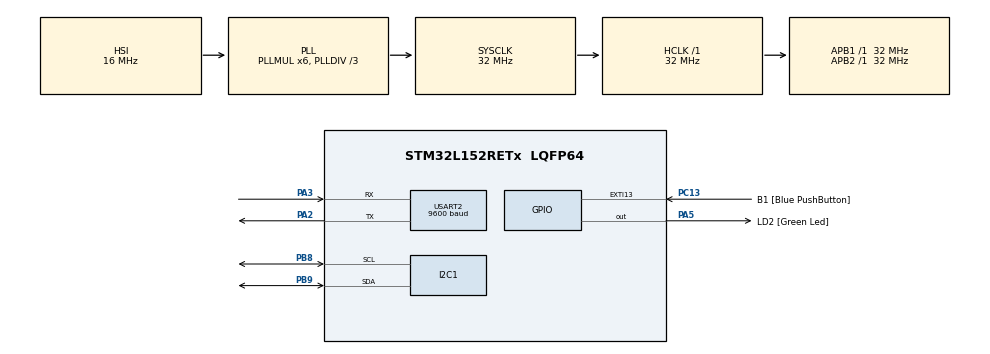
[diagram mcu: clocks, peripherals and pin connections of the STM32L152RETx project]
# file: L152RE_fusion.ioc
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Mcu.Family=STM32L1
Mcu.Name=STM32L152RETx
Mcu.Package=LQFP64
NVIC.PriorityGroup=NVIC_PRIORITYGROUP_0
NVIC.RCC_IRQn=true\:0\:0\:false\:false\:true\:true
NVIC.TIM3_IRQn=true\:0\:0\:false\:false\:true\:true
PA2.Mode=Asynchronous
PA2.Signal=USART2_TX
PA3.Mode=Asynchronous
PA3.Signal=USART2_RX
PA5.GPIO_Label=LD2 [Green Led]
PA5.Signal=GPIO_Output
PB8.Mode=I2C
PB8.Signal=I2C1_SCL
PB9.Mode=I2C
PB9.Signal=I2C1_SDA
PC13-WKUP2.GPIO_Label=B1 [Blue PushButton]
PC13-WKUP2.Signal=GPXTI13
PH0-OSC_IN.Mode=HSE-External-Oscillator
PH0-OSC_IN.Signal=RCC_OSC_IN
PH1-OSC_OUT.Mode=HSE-External-Oscillator
PH1-OSC_OUT.Signal=RCC_OSC_OUT
ProjectManager.HeapSize=0x200
ProjectManager.StackSize=0x400
ProjectManager.TargetToolchain=SW4STM32
RCC.AHBFreq_Value=32000000
RCC.APB1Freq_Value=32000000
RCC.APB1TimFreq_Value=32000000
RCC.APB2Freq_Value=32000000
RCC.APB2TimFreq_Value=32000000
RCC.HCLKFreq_Value=32000000
RCC.HSE_VALUE=8000000
RCC.HSI_VALUE=16000000
RCC.LSE_VALUE=32768
RCC.MSI_VALUE=2097000
RCC.PLLDIV=RCC_PLL_DIV3
RCC.PLLMUL=RCC_PLL_MUL6
RCC.RTCClockSelectionVirtual=RCC_RTCCLKSOURCE_LSE
RCC.SYSCLKFreq_VALUE=32000000
RCC.SYSCLKSource=RCC_SYSCLKSOURCE_PLLCLK
RCC.USBOutput=48000000
RCC.VCOOutputFreq_Value=96000000
TIM3.Period=499
TIM3.Prescaler=15999
USART2.BaudRate=9600
USART2.VirtualMode=VM_ASYNC
VP_TIM3_VS_ClockSourceINT.Mode=Internal
board=NUCLEO-L152RE

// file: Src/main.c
/**
 ******************************************************************************
 * File Name          : main.c
 * Description        : Main program body
 ******************************************************************************
 ******************************************************************************
 */

#include "main.h"
#include "stm32l1xx_hal.h"

/* USER CODE BEGIN Includes */
#include "LSM303AGR_driver.h"
#include <stdio.h>
#include <stdarg.h>
#include <string.h>
/* USER CODE END Includes */

I2C_HandleTypeDef hi2c1;
TIM_HandleTypeDef htim3;
UART_HandleTypeDef huart2;

/* USER CODE BEGIN PV */
/* Private variables ---------------------------------------------------------*/

/* USER CODE END PV */

void SystemClock_Config(void);
static void MX_GPIO_Init(void);
static void MX_I2C1_Init(void);
static void MX_USART2_UART_Init(void);
static void MX_TIM3_Init(void);

/* USER CODE BEGIN PFP */
/* Private function prototypes -----------------------------------------------*/

/* USER CODE END PFP */
void vprint(const char *fmt, va_list argp);
void my_printf(const char *fmt);
//void write_register(uint8_t register_pointer, uint16_t register_value);
//void read_register(uint8_t register_pointer, uint16_t register_value);
/* USER CODE END PFP */

int main(void) {

	/* MCU Configuration----------------------------------------------------------*/
	/* Reset of all peripherals, Initializes the Flash interface and the Systick. */
	HAL_Init();

	/* Configure the system clock */
	SystemClock_Config();

	/* Initialize all configured peripherals */
	MX_GPIO_Init();
	MX_I2C1_Init();
	MX_USART2_UART_Init();
	MX_TIM3_Init();

	/* Infinite loop */
	while (1) {

//		char message[] = "Start test\n\r";
//
//		HAL_UART_Transmit(&huart2, (uint8_t*)message, strlen(message), 1000);
//		HAL_Delay(2000);
//
//		/* USER CODE BEGIN 3 */
//		//https://electronics.stackexchange.com/questions/244491/addressing-registers-with-i2c-stm32f0-hal-libraries
//		uint8_t buffer = 0b01000001;
//
//		// Set the register pointer to the register wanted to be read
//		HAL_I2C_Master_Transmit(&hi2c1, LSM303AGR_M_I2C_ADDRESS<<1,
//				LSM303AGR_A_WHO_AM_I_REG, 1, 100);
//
//		// Receive the 8-bit data into the buffer
//		HAL_I2C_Master_Receive(&hi2c1, LSM303AGR_A_I2C_ADDRESS, buffer, 1, 100);
//
//		char message1[] = "start I2C reading\n\r";
//		HAL_UART_Transmit(&huart2, (uint8_t*)message1, strlen(message1), 1000);
//		HAL_Delay(1000);
//
//		//HAL_I2C_Mem_Read(&hi2c1, 0b0011110 >> 1,
//				//0b0001111, I2C_MEMADD_SIZE_8BIT, &buffer, 1, 100);
//		//HAL_Delay(500);
//		char message2[] = "I2C reading finished\n\r";
//		HAL_UART_Transmit(&huart2, (uint8_t*)message2, strlen(message2), 1000);
//		char bufferChar = (char) buffer;
//		HAL_UART_Transmit(&huart2, (uint8_t*)bufferChar, strlen(bufferChar), 1000);
//		HAL_Delay(2000);

		uint16_t year = 2015;
		uint8_t month = 12;
		uint8_t day   = 18;
		char* date = "date";

		// "Today's date: 2015-12-18"
		my_printf("Today's %s: %d-%d-%d\r\n");
		HAL_Delay(500);

	}

}

/** System Clock Configuration */
void SystemClock_Config(void) {

	RCC_OscInitTypeDef RCC_OscInitStruct;
	RCC_ClkInitTypeDef RCC_ClkInitStruct;

	/**Configure the main internal regulator output voltage
	 */
	__HAL_PWR_VOLTAGESCALING_CONFIG(PWR_REGULATOR_VOLTAGE_SCALE1);

	/**Initializes the CPU, AHB and APB busses clocks
	 */
	RCC_OscInitStruct.OscillatorType = RCC_OSCILLATORTYPE_HSI;
	RCC_OscInitStruct.HSIState = RCC_HSI_ON;
	RCC_OscInitStruct.HSICalibrationValue = 16;
	RCC_OscInitStruct.PLL.PLLState = RCC_PLL_ON;
	RCC_OscInitStruct.PLL.PLLSource = RCC_PLLSOURCE_HSI;
	RCC_OscInitStruct.PLL.PLLMUL = RCC_PLL_MUL6;
	RCC_OscInitStruct.PLL.PLLDIV = RCC_PLL_DIV3;
	if (HAL_RCC_OscConfig(&RCC_OscInitStruct) != HAL_OK) {
		_Error_Handler(__FILE__, __LINE__);
	}

	/**Initializes the CPU, AHB and APB busses clocks
	 */
	RCC_ClkInitStruct.ClockType = RCC_CLOCKTYPE_HCLK | RCC_CLOCKTYPE_SYSCLK
			| RCC_CLOCKTYPE_PCLK1 | RCC_CLOCKTYPE_PCLK2;
	RCC_ClkInitStruct.SYSCLKSource = RCC_SYSCLKSOURCE_PLLCLK;
	RCC_ClkInitStruct.AHBCLKDivider = RCC_SYSCLK_DIV1;
	RCC_ClkInitStruct.APB1CLKDivider = RCC_HCLK_DIV1;
	RCC_ClkInitStruct.APB2CLKDivider = RCC_HCLK_DIV1;

	if (HAL_RCC_ClockConfig(&RCC_ClkInitStruct, FLASH_LATENCY_1) != HAL_OK) {
		_Error_Handler(__FILE__, __LINE__);
	}

	/**Configure the Systick interrupt time
	 */
	HAL_SYSTICK_Config(HAL_RCC_GetHCLKFreq() / 1000);

	/**Configure the Systick
	 */
	HAL_SYSTICK_CLKSourceConfig(SYSTICK_CLKSOURCE_HCLK);

	/* SysTick_IRQn interrupt configuration
	 */
	HAL_NVIC_SetPriority(SysTick_IRQn, 0, 0);
}

/* I2C1 init function */
static void MX_I2C1_Init(void) {

	hi2c1.Instance = I2C1;
	hi2c1.Init.ClockSpeed = 100000;
	hi2c1.Init.DutyCycle = I2C_DUTYCYCLE_2;
	hi2c1.Init.OwnAddress1 = 0;
	hi2c1.Init.AddressingMode = I2C_ADDRESSINGMODE_7BIT;
	hi2c1.Init.DualAddressMode = I2C_DUALADDRESS_DISABLE;
	hi2c1.Init.OwnAddress2 = 0;
	hi2c1.Init.GeneralCallMode = I2C_GENERALCALL_DISABLE;
	hi2c1.Init.NoStretchMode = I2C_NOSTRETCH_DISABLE;
	if (HAL_I2C_Init(&hi2c1) != HAL_OK) {
		_Error_Handler(__FILE__, __LINE__);
	}

}

/* TIM3 init function */
static void MX_TIM3_Init(void) {

	TIM_ClockConfigTypeDef sClockSourceConfig;
	TIM_MasterConfigTypeDef sMasterConfig;

	htim3.Instance = TIM3;
	htim3.Init.Prescaler = 15999;
	htim3.Init.CounterMode = TIM_COUNTERMODE_UP;
	htim3.Init.Period = 499;
	htim3.Init.ClockDivision = TIM_CLOCKDIVISION_DIV1;
	if (HAL_TIM_Base_Init(&htim3) != HAL_OK) {
		_Error_Handler(__FILE__, __LINE__);
	}

	sClockSourceConfig.ClockSource = TIM_CLOCKSOURCE_INTERNAL;
	if (HAL_TIM_ConfigClockSource(&htim3, &sClockSourceConfig) != HAL_OK) {
		_Error_Handler(__FILE__, __LINE__);
	}

	sMasterConfig.MasterOutputTrigger = TIM_TRGO_RESET;
	sMasterConfig.MasterSlaveMode = TIM_MASTERSLAVEMODE_DISABLE;
	if (HAL_TIMEx_MasterConfigSynchronization(&htim3, &sMasterConfig)
			!= HAL_OK) {
		_Error_Handler(__FILE__, __LINE__);
	}

}

/* USART2 init function */
static void MX_USART2_UART_Init(void) {

	huart2.Instance = USART2;
	huart2.Init.BaudRate = 9600;
	huart2.Init.WordLength = UART_WORDLENGTH_8B;
	huart2.Init.StopBits = UART_STOPBITS_1;
	huart2.Init.Parity = UART_PARITY_NONE;
	huart2.Init.Mode = UART_MODE_TX_RX;
	huart2.Init.HwFlowCtl = UART_HWCONTROL_NONE;
	huart2.Init.OverSampling = UART_OVERSAMPLING_16;
	if (HAL_UART_Init(&huart2) != HAL_OK) {
		_Error_Handler(__FILE__, __LINE__);
	}

}

/** Configure pins as
 * Analog
 * Input
 * Output
 * EVENT_OUT
 * EXTI
 */
static void MX_GPIO_Init(void) {

	GPIO_InitTypeDef GPIO_InitStruct;

	/* GPIO Ports Clock Enable */
	__HAL_RCC_GPIOC_CLK_ENABLE()
	;
	__HAL_RCC_GPIOH_CLK_ENABLE()
	;
	__HAL_RCC_GPIOA_CLK_ENABLE()
	;
	__HAL_RCC_GPIOB_CLK_ENABLE()
	;

	/*Configure GPIO pin Output Level */
	HAL_GPIO_WritePin(LD2_GPIO_Port, LD2_Pin, GPIO_PIN_RESET);

	/*Configure GPIO pin : B1_Pin */
	GPIO_InitStruct.Pin = B1_Pin;
	GPIO_InitStruct.Mode = GPIO_MODE_IT_RISING;
	GPIO_InitStruct.Pull = GPIO_NOPULL;
	HAL_GPIO_Init(B1_GPIO_Port, &GPIO_InitStruct);

	/*Configure GPIO pin : LD2_Pin */
	GPIO_InitStruct.Pin = LD2_Pin;
	GPIO_InitStruct.Mode = GPIO_MODE_OUTPUT_PP;
	GPIO_InitStruct.Pull = GPIO_NOPULL;
	GPIO_InitStruct.Speed = GPIO_SPEED_FREQ_LOW;
	HAL_GPIO_Init(LD2_GPIO_Port, &GPIO_InitStruct);

}

/* USER CODE BEGIN 4 */

void vprint(const char *fmt, va_list argp)
{
    char string[200];
    if(0 < vsprintf(string,fmt,argp)) // build string
    {
        HAL_UART_Transmit(&huart2, (uint8_t*)string, strlen(string), 0xffffff); // send message via UART
    }
}

void my_printf(const char *fmt) // custom printf() function
{
    va_list argps;
    va_start(argps, fmt);
    vprint(fmt, argps);
    va_end(argps);
}

//void write_register(uint8_t register_pointer, uint16_t register_value) {
//	HAL_StatusTypeDef status = HAL_OK;
//
//	//status = HAL_I2C_Mem_Write();
//
//	if (status != HAL_OK) {
//		//Error handling
//	}
//}
/* USER CODE END 4 */

void _Error_Handler(char * file, int line) {
	while (1) {
	}
}

/************************ (C) COPYRIGHT STMicroelectronics *****END OF FILE****/
